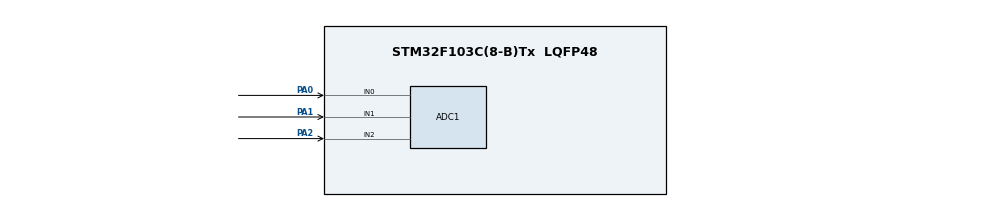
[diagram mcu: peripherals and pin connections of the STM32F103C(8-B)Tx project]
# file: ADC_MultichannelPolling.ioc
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ADC1.Channel-0\#ChannelRegularConversion=ADC_CHANNEL_0
ADC1.NbrOfConversion=1
ADC1.NbrOfConversionFlag=1
ADC1.Rank-0\#ChannelRegularConversion=1
ADC1.SamplingTime-0\#ChannelRegularConversion=ADC_SAMPLETIME_1CYCLE_5
ADC1.master=1
Mcu.Family=STM32F1
Mcu.Name=STM32F103C(8-B)Tx
Mcu.Package=LQFP48
NVIC.PriorityGroup=NVIC_PRIORITYGROUP_4
PA0-WKUP.Signal=ADCx_IN0
PA1.Signal=ADCx_IN1
PA2.Signal=ADCx_IN2
PD0-OSC_IN.Mode=HSE-External-Oscillator
PD0-OSC_IN.Signal=RCC_OSC_IN
PD1-OSC_OUT.Mode=HSE-External-Oscillator
PD1-OSC_OUT.Signal=RCC_OSC_OUT
ProjectManager.HeapSize=0x200
ProjectManager.StackSize=0x400
ProjectManager.TargetToolchain=STM32CubeIDE
RCC.APB1Freq_Value=8000000
RCC.APB2Freq_Value=8000000
SH.ADCx_IN0.0=ADC1_IN0,IN0
SH.ADCx_IN1.0=ADC1_IN1,IN1
SH.ADCx_IN2.0=ADC1_IN2,IN2
VP_SYS_VS_ND.Mode=No_Debug
board=custom

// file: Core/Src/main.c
/* USER CODE BEGIN Header */
/**
  ******************************************************************************
  * @file           : main.c
  * @brief          : Main program body
  ******************************************************************************
  * @attention
  *
  * Copyright (c) 2024 STMicroelectronics.
  * All rights reserved.
  *
  * This software is licensed under terms that can be found in the LICENSE file
  * in the root directory of this software component.
  * If no LICENSE file comes with this software, it is provided AS-IS.
  *
  ******************************************************************************
  */
/* USER CODE END Header */
#include "main.h"
#include "adc.h"
#include "gpio.h"

/* USER CODE BEGIN PV */
uint16_t ADC_VAL[3] = {0};
/* USER CODE END PV */

void SystemClock_Config(void);
/* USER CODE BEGIN PFP */
void ADC_Select_CH0 (void);
void ADC_Select_CH1 (void);
void ADC_Select_CH2 (void);
/* USER CODE END PFP */

int main(void)
{

  /* MCU Configuration--------------------------------------------------------*/

  /* Reset of all peripherals, Initializes the Flash interface and the Systick. */
  HAL_Init();

  /* Configure the system clock */
  SystemClock_Config();

  /* Initialize all configured peripherals */
  MX_GPIO_Init();
  MX_ADC1_Init();

  /* Infinite loop */
  /* USER CODE BEGIN WHILE */
  while (1)
  {
	ADC_Select_CH0();
	HAL_ADC_Start(&hadc1);
	HAL_ADC_PollForConversion(&hadc1, 100);
	ADC_VAL[0] = HAL_ADC_GetValue(&hadc1);
	HAL_ADC_Stop(&hadc1);

	ADC_Select_CH1();
	HAL_ADC_Start(&hadc1);
	HAL_ADC_PollForConversion(&hadc1, 100);
	ADC_VAL[1] = HAL_ADC_GetValue(&hadc1);
	HAL_ADC_Stop(&hadc1);

	ADC_Select_CH2();
	HAL_ADC_Start(&hadc1);
	HAL_ADC_PollForConversion(&hadc1, 100);
	ADC_VAL[2] = HAL_ADC_GetValue(&hadc1);
	HAL_ADC_Stop(&hadc1);

	HAL_Delay(500);
    /* USER CODE END WHILE */

  }
}

void SystemClock_Config(void)
{
  RCC_OscInitTypeDef RCC_OscInitStruct = {0};
  RCC_ClkInitTypeDef RCC_ClkInitStruct = {0};
  RCC_PeriphCLKInitTypeDef PeriphClkInit = {0};

  /** Initializes the RCC Oscillators according to the specified parameters
  * in the RCC_OscInitTypeDef structure.
  */
  RCC_OscInitStruct.OscillatorType = RCC_OSCILLATORTYPE_HSI;
  RCC_OscInitStruct.HSIState = RCC_HSI_ON;
  RCC_OscInitStruct.HSICalibrationValue = RCC_HSICALIBRATION_DEFAULT;
  RCC_OscInitStruct.PLL.PLLState = RCC_PLL_NONE;
  if (HAL_RCC_OscConfig(&RCC_OscInitStruct) != HAL_OK)
  {
    Error_Handler();
  }

  /** Initializes the CPU, AHB and APB buses clocks
  */
  RCC_ClkInitStruct.ClockType = RCC_CLOCKTYPE_HCLK|RCC_CLOCKTYPE_SYSCLK
                              |RCC_CLOCKTYPE_PCLK1|RCC_CLOCKTYPE_PCLK2;
  RCC_ClkInitStruct.SYSCLKSource = RCC_SYSCLKSOURCE_HSI;
  RCC_ClkInitStruct.AHBCLKDivider = RCC_SYSCLK_DIV1;
  RCC_ClkInitStruct.APB1CLKDivider = RCC_HCLK_DIV1;
  RCC_ClkInitStruct.APB2CLKDivider = RCC_HCLK_DIV1;

  if (HAL_RCC_ClockConfig(&RCC_ClkInitStruct, FLASH_LATENCY_0) != HAL_OK)
  {
    Error_Handler();
  }
  PeriphClkInit.PeriphClockSelection = RCC_PERIPHCLK_ADC;
  PeriphClkInit.AdcClockSelection = RCC_ADCPCLK2_DIV2;
  if (HAL_RCCEx_PeriphCLKConfig(&PeriphClkInit) != HAL_OK)
  {
    Error_Handler();
  }
}

/* USER CODE BEGIN 4 */
void ADC_Select_CH0 (void)
{
	ADC_ChannelConfTypeDef sConfig = {0};
	  /** Configure for the selected ADC regular channel its corresponding rank in the sequencer and its sample time.
	  */
	  sConfig.Channel = ADC_CHANNEL_0;
	  sConfig.Rank = 1;
	  sConfig.SamplingTime = ADC_SAMPLETIME_1CYCLE_5;
	  if (HAL_ADC_ConfigChannel(&hadc1, &sConfig) != HAL_OK)
	  {
	    Error_Handler();
	  }
}

void ADC_Select_CH1 (void)
{
	ADC_ChannelConfTypeDef sConfig = {0};
	  /** Configure for the selected ADC regular channel its corresponding rank in the sequencer and its sample time.
	  */
	  sConfig.Channel = ADC_CHANNEL_1;
	  sConfig.Rank = 1;
	  sConfig.SamplingTime = ADC_SAMPLETIME_1CYCLE_5;
	  if (HAL_ADC_ConfigChannel(&hadc1, &sConfig) != HAL_OK)
	  {
	    Error_Handler();
	  }
}

void ADC_Select_CH2 (void)
{
	ADC_ChannelConfTypeDef sConfig = {0};
	  /** Configure for the selected ADC regular channel its corresponding rank in the sequencer and its sample time.
	  */
	  sConfig.Channel = ADC_CHANNEL_2;
	  sConfig.Rank = 1;
	  sConfig.SamplingTime = ADC_SAMPLETIME_1CYCLE_5;
	  if (HAL_ADC_ConfigChannel(&hadc1, &sConfig) != HAL_OK)
	  {
	    Error_Handler();
	  }
}
/* USER CODE END 4 */

void Error_Handler(void)
{
  __disable_irq();
  while (1)
  {
  }
}
